# K1921VG015 register map
Vendor: NIIET; Series: K1921Vxxx; File version: 1.14
Registers are 32-bit, read-write, reset 0x0 unless marked. A register's access mark holds for its fields unless they carry their own. Offsets are from the block's base; [hi:lo] are bit positions; lines under a group give offsets from that group; {n}, {i} and the like mark numbered series.

## TRNG — Random Number Generators (TRNG) control registers
Base 0x30004000
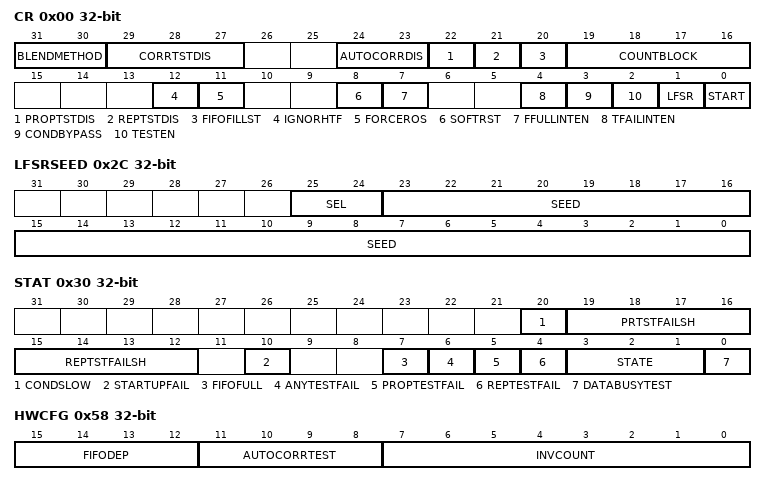
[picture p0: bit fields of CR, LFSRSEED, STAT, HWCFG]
0x00 CR — Control register
  [31:30] BLENDMETHOD — Select blending method: 00: Concatenation; 01: XOR_LEVEL_1; 10: XOR_LEVEL_2; 11: VON-NEUMANN debiasing
    0=Concatenation (Blending method Concatenation); 1=XOR_LEVEL_1 (Blending method XOR_LEVEL_1); 2=XOR_LEVEL_2 (Blending method XOR_LEVEL_2); 3=VON_NEUMANN_debiasing (Blending method VON_NEUMANN_debiasing)
  [29:27] CORRTSTDIS — Disable speci1c delay(s) check in correlation test - different ROs: xx1: vs. the same sample of the other RO -> (0) delay check x1x: vs. the preceding sample of the other RO -> (-1) delay check 1xx: vs. the next sample of the other RO -> (+1) delay check
  [24:23] AUTOCORRDIS — Disable speci1c delay(s) check in auto-correlation test - same RO: x1: vs. the following sample of the same RO -> (0) delay check 1x: vs. the later sample of the same RO -> (+1) delay check
  [22] PROPTSTDIS — All proportion tests (each share) are disabled via this single bit
  [21] REPTSTDIS — All repetition tests (each share) are disabled via this single bit
  [20] FIFOFILLST — Enable write of the samples in the FIFO during start-up
  [19:16] COUNTBLOCK — Number of 128-bit blocks used in conditioning (AES-CBC-MAC) post-processing. Zero value is not allowed
  [12] IGNORHTF — Results of the health tests during start-up and online test do not affect the control FSM state. It also bypass control FSM StartUp phase
  [11] FORCEROS — Force oscillators to run when FIFO is full
  [8] SOFTRST — Datapath content 2ush and control FSM reset: 0: Normal mode; 1: Datapath components - the health tests, the conditioning function and the FIFO - are cleared. This bit is not cleared automatically. Configuration registers preserve their values. Send control FSM to Reset state.
  [7] FFULLINTEN — Enable interrupt if FIFO is full
  [4] TFAILINTEN — Enable interrupt if any of the health test fails
  [3] CONDBYPASS — 0: Conditioning function is used (normal mode); 1: Conditioning function is bypassed (to observe entropy source directly)
  [2] TESTEN — Select input for conditioning function and continuous tests: 0: Noise source (normal mode) 1: Test data register (test mode)
  [1] LFSR — Select between the NDRNG with asynchronous free running oscillators (when 0) and the Pseudo-Random generator with synchronous oscillators
    0=AsyncFreeRunOsc (NDRNG with asynchronous free running oscillators); 1=SyncOsc (Pseudo-Random generator with synchronous oscillators for simulation purpose)
  [0] START — Start/enable the NDRNG
0x04 FIFOLEV — FIFOLevel register
  [31:0] VAL — Number of 32 bits words of random available in the FIFO. Any write to this register clears the FifoFull 2ag in the Status register.
0x08 FIFOTHR — FIFOThreshold register
  [6:0] VAL — FIFO level below which the module starts to refill the FIFO, expressed in number of 128bit blocks.
0x0C FIFODEP ro — FIFODepth register
  [31:0] VAL — Maximum number of 32 bits words that can be stored in the FIFO
{0x10+4i} KEY[{i}] (i=0..3) group
  0x00 KEY
    [31:0] VAL — Bits form the 128-bit AES key
0x20 TESTDATA wo
  [31:0] VAL — Test data
0x24 REPTSTCUTOFF — Cut-off value for the repetition tests register
  [5:0] VAL — Cut-off value for the repetition tests
0x28 PROPTESTCUTOFF — Proportion test cut-off value register
  [8:0] VAL — Proportion test cut-off value
0x2C LFSRSEED
  [25:24] SEL wo — Share index for which initialization value should be used
  [23:0] SEED — LFSR initialization value
0x30 STAT — Status register
  [20] CONDSLOW — Conditioning consumes data slower than they are provided to it
  [19:16] PRTSTFAILSH ro — NIST Proportion test failure per share
  [15:12] REPTSTFAILSH ro — NIST Repetition test failure per share
  [10] STARTUPFAIL — Start-up test(s) failure
  [7] FIFOFULL — FIFO full status
  [6] ANYTESTFAIL — Any of the enabled health tests is failing
  [5] PROPTESTFAIL — NIST Proportion test(s) failure
  [4] REPTESTFAIL — NIST Repetition test(s) failure
  [3:1] STATE ro — State of the control FSM
    on read: 0=Reset (State Reset); 1=StartUp (State Startup); 2=Idle_FIFOfull (State Idle / FIFO full); 4=FIFOfill (State Fill FIFO); 5=Error (State Error)
  [0] DATABUSYTEST ro — High when data written to TestData register is being processed
0x34 WARMPERIOD — WarmupPeriod register
  [31:0] VAL — Number of clock cycles to wait during warm-up sequence
0x38 DISOSC — DisableOsc registers
  [7:0] VAL — Disable oscillator rings 0 to size-1
0x44 SAMPERIOD — SamplingPeriod register
  [31:0] VAL — Number of clock cycles to wait between sampling moments
0x58 HWCFG ro — HW Configuration register
  [15:12] FIFODEP — Generic g_Log2FifoDepth value
  [11:8] AUTOCORRTEST — Generic g_Log2NbOfAutoCorrTestsPerShare value
  [7:0] INVCOUNT — Generic g_NbOfInverters value
0x5C COOLDPERIOD — CooldownPeriod register
  [31:0] VAL — Number of clock cycles to wait during cool-down sequence
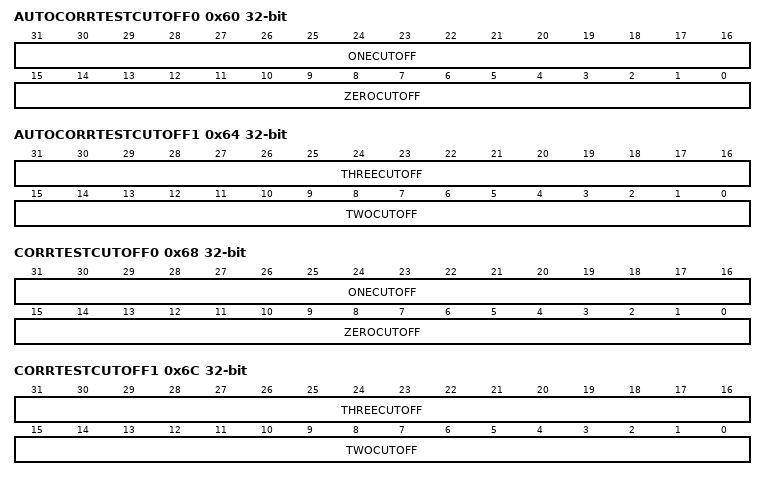
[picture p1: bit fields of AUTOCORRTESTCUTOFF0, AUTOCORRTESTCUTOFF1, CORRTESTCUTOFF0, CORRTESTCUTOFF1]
0x60 AUTOCORRTESTCUTOFF0 — AutoCorrTestCutoff register 0
  [31:16] ONECUTOFF — Auto-correlation test cut-off value for delay of +1 sample
  [15:0] ZEROCUTOFF — Auto-correlation test cut-off value for delay of 0 samples
0x64 AUTOCORRTESTCUTOFF1 — AutoCorrTestCutoff register 1
  [31:16] THREECUTOFF — Auto-correlation test cut-off value for delay +3 samples
  [15:0] TWOCUTOFF — Auto-correlation test cut-off value for delay +2 samples
0x68 CORRTESTCUTOFF0 — CorrTestCutoff register 0
  [31:16] ONECUTOFF — Correlation test cut-off value for time shift/delay of +/-1 sample
  [15:0] ZEROCUTOFF — Correlation test cut-off value for time shift/delay of 0 samples
0x6C CORRTESTCUTOFF1 — CorrTestCutoff register 1
  [31:16] THREECUTOFF — Correlation test cut-off value for time shift/delay of +/-3 samples
  [15:0] TWOCUTOFF — Correlation test cut-off value for time shift/delay of +/-2 samples
0x70 AUTOCORRTESTFAILED ro
  [7:0] VAL — Auto-correlation test failing ring(s)
0x74 CORRTESTFAILED ro
  [7:0] VAL — Correlation test failing rings
0x7C HWVERSION ro
  [0] HWVER
{0x80+4i} FIFO[{i}] (i=0..31) group
  0x00 FIFO ro
    [31:0] VAL — Result
